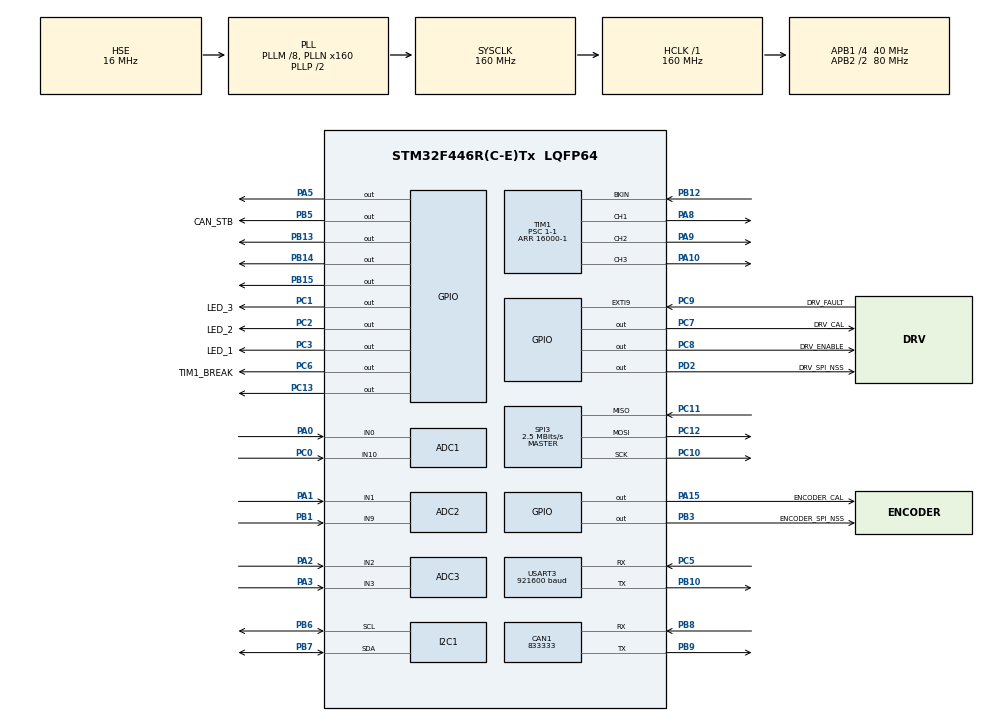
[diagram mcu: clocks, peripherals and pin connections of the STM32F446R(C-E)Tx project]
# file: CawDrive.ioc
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ADC1.Channel-0\#ChannelRegularConversion=ADC_CHANNEL_10
ADC1.Channel-1\#ChannelInjectedConversion=ADC_CHANNEL_0
ADC1.ExternalTrigInjecConv=ADC_EXTERNALTRIGINJECCONV_T1_CC4
ADC1.InjNumberOfConversion=1
ADC1.InjectedOffset-1\#ChannelInjectedConversion=0
ADC1.InjectedRank-1\#ChannelInjectedConversion=1
ADC1.NbrOfConversionFlag=1
ADC1.Rank-0\#ChannelRegularConversion=1
ADC1.SamplingTime-0\#ChannelRegularConversion=ADC_SAMPLETIME_3CYCLES
ADC1.SamplingTime-1\#ChannelInjectedConversion=ADC_SAMPLETIME_3CYCLES
ADC1.master=1
ADC2.Channel-1\#ChannelRegularConversion=ADC_CHANNEL_9
ADC2.Channel-2\#ChannelInjectedConversion=ADC_CHANNEL_1
ADC2.ExternalTrigInjecConv=ADC_EXTERNALTRIGINJECCONV_T1_CC4
ADC2.InjNumberOfConversion=1
ADC2.InjectedOffset-2\#ChannelInjectedConversion=0
ADC2.InjectedRank-2\#ChannelInjectedConversion=1
ADC2.NbrOfConversionFlag=1
ADC2.Rank-1\#ChannelRegularConversion=1
ADC2.SamplingTime-1\#ChannelRegularConversion=ADC_SAMPLETIME_3CYCLES
ADC2.SamplingTime-2\#ChannelInjectedConversion=ADC_SAMPLETIME_3CYCLES
ADC3.Channel-0\#ChannelRegularConversion=ADC_CHANNEL_3
ADC3.Channel-1\#ChannelInjectedConversion=ADC_CHANNEL_2
ADC3.ExternalTrigInjecConv=ADC_EXTERNALTRIGINJECCONV_T1_CC4
ADC3.InjNumberOfConversion=1
ADC3.InjectedOffset-1\#ChannelInjectedConversion=0
ADC3.InjectedRank-1\#ChannelInjectedConversion=1
ADC3.NbrOfConversionFlag=1
ADC3.Rank-0\#ChannelRegularConversion=1
ADC3.SamplingTime-0\#ChannelRegularConversion=ADC_SAMPLETIME_3CYCLES
ADC3.SamplingTime-1\#ChannelInjectedConversion=ADC_SAMPLETIME_3CYCLES
CAN1.BS1=CAN_BS1_1TQ
CAN1.BS2=CAN_BS2_1TQ
CAN1.CalculateBaudRate=833333
CAN1.CalculateTimeBit=1200
CAN1.CalculateTimeQuantum=400.0
Dma.Request0=USART3_TX
Dma.Request1=USART3_RX
Dma.USART3_RX.1.Direction=DMA_PERIPH_TO_MEMORY
Dma.USART3_RX.1.FIFOMode=DMA_FIFOMODE_DISABLE
Dma.USART3_RX.1.Instance=DMA1_Stream1
Dma.USART3_RX.1.MemDataAlignment=DMA_MDATAALIGN_BYTE
Dma.USART3_RX.1.MemInc=DMA_MINC_ENABLE
Dma.USART3_RX.1.Mode=DMA_NORMAL
Dma.USART3_RX.1.PeriphDataAlignment=DMA_PDATAALIGN_BYTE
Dma.USART3_RX.1.PeriphInc=DMA_PINC_DISABLE
Dma.USART3_RX.1.Priority=DMA_PRIORITY_LOW
Dma.USART3_TX.0.Direction=DMA_MEMORY_TO_PERIPH
Dma.USART3_TX.0.FIFOMode=DMA_FIFOMODE_DISABLE
Dma.USART3_TX.0.Instance=DMA1_Stream3
Dma.USART3_TX.0.MemDataAlignment=DMA_MDATAALIGN_BYTE
Dma.USART3_TX.0.MemInc=DMA_MINC_ENABLE
Dma.USART3_TX.0.Mode=DMA_NORMAL
Dma.USART3_TX.0.PeriphDataAlignment=DMA_PDATAALIGN_BYTE
Dma.USART3_TX.0.PeriphInc=DMA_PINC_DISABLE
Dma.USART3_TX.0.Priority=DMA_PRIORITY_LOW
Mcu.Family=STM32F4
Mcu.Name=STM32F446R(C-E)Tx
Mcu.Package=LQFP64
NVIC.ADC_IRQn=true\:0\:0\:false\:false\:true\:true\:true\:true
NVIC.DMA1_Stream1_IRQn=true\:0\:0\:false\:false\:true\:false\:true\:true
NVIC.DMA1_Stream3_IRQn=true\:0\:0\:false\:false\:true\:false\:true\:true
NVIC.PriorityGroup=NVIC_PRIORITYGROUP_4
NVIC.TIM1_BRK_TIM9_IRQn=true\:0\:0\:false\:false\:true\:true\:true\:true
NVIC.TIM1_CC_IRQn=true\:0\:0\:false\:false\:true\:true\:true\:true
NVIC.TIM1_UP_TIM10_IRQn=true\:0\:0\:false\:false\:true\:true\:true\:true
NVIC.TIM3_IRQn=true\:0\:0\:false\:false\:true\:true\:true\:true
NVIC.TIM6_DAC_IRQn=true\:15\:0\:false\:false\:true\:false\:true\:true
NVIC.TimeBase=TIM6_DAC_IRQn
NVIC.TimeBaseIP=TIM6
NVIC.USART3_IRQn=true\:0\:0\:false\:false\:true\:true\:true\:true
PA0-WKUP.Signal=ADCx_IN0
PA1.Signal=ADCx_IN1
PA10.Signal=S_TIM1_CH3
PA13.Mode=Serial_Wire
PA13.Signal=SYS_JTMS-SWDIO
PA14.Mode=Serial_Wire
PA14.Signal=SYS_JTCK-SWCLK
PA15.GPIO_Label=ENCODER_CAL
PA15.Signal=GPIO_Output
PA2.Signal=ADCx_IN2
PA3.Signal=ADCx_IN3
PA5.Signal=GPIO_Output
PA6.Signal=S_TIM3_CH1
PA7.Signal=S_TIM3_CH2
PA8.Signal=S_TIM1_CH1
PA9.Signal=S_TIM1_CH2
PB0.Signal=S_TIM3_CH3
PB1.Signal=ADCx_IN9
PB10.Mode=Asynchronous
PB10.Signal=USART3_TX
PB12.Mode=Activate-Break-Input
PB12.Signal=TIM1_BKIN
PB13.PinState=GPIO_PIN_RESET
PB13.Signal=GPIO_Output
PB14.PinState=GPIO_PIN_RESET
PB14.Signal=GPIO_Output
PB15.PinState=GPIO_PIN_RESET
PB15.Signal=GPIO_Output
PB3.GPIO_Label=ENCODER_SPI_NSS
PB3.PinState=GPIO_PIN_SET
PB3.Signal=GPIO_Output
PB5.GPIO_Label=CAN_STB
PB5.Signal=GPIO_Output
PB6.Mode=I2C
PB6.Signal=I2C1_SCL
PB7.Mode=I2C
PB7.Signal=I2C1_SDA
PB8.Mode=CAN_Activate
PB8.Signal=CAN1_RX
PB9.Mode=CAN_Activate
PB9.Signal=CAN1_TX
PC0.Signal=ADCx_IN10
PC1.GPIO_Label=LED_3
PC1.Signal=GPIO_Output
PC10.Mode=Full_Duplex_Master
PC10.Signal=SPI3_SCK
PC11.Mode=Full_Duplex_Master
PC11.Signal=SPI3_MISO
PC12.Mode=Full_Duplex_Master
PC12.Signal=SPI3_MOSI
PC13.Signal=GPIO_Output
PC2.GPIO_Label=LED_2
PC2.Signal=GPIO_Output
PC3.GPIO_Label=LED_1
PC3.Signal=GPIO_Output
PC5.Mode=Asynchronous
PC5.Signal=USART3_RX
PC6.GPIO_Label=TIM1_BREAK
PC6.Signal=GPIO_Output
PC7.GPIO_Label=DRV_CAL
PC7.Signal=GPIO_Output
PC8.GPIO_Label=DRV_ENABLE
PC8.Signal=GPIO_Output
PC9.GPIO_Label=DRV_FAULT
PC9.Signal=GPXTI9
PD2.GPIO_Label=DRV_SPI_NSS
PD2.PinState=GPIO_PIN_SET
PD2.Signal=GPIO_Output
PH0-OSC_IN.Mode=HSE-External-Oscillator
PH0-OSC_IN.Signal=RCC_OSC_IN
PH1-OSC_OUT.Mode=HSE-External-Oscillator
PH1-OSC_OUT.Signal=RCC_OSC_OUT
ProjectManager.HeapSize=0x200
ProjectManager.StackSize=0x400
ProjectManager.TargetToolchain=Makefile
RCC.AHBFreq_Value=160000000
RCC.APB1CLKDivider=RCC_HCLK_DIV4
RCC.APB1Freq_Value=40000000
RCC.APB1TimFreq_Value=80000000
RCC.APB2CLKDivider=RCC_HCLK_DIV2
RCC.APB2Freq_Value=80000000
RCC.APB2TimFreq_Value=160000000
RCC.CortexFreq_Value=160000000
RCC.HCLKFreq_Value=160000000
RCC.HSE_VALUE=16000000
RCC.PLLM=8
RCC.PLLN=160
RCC.PLLSourceVirtual=RCC_PLLSOURCE_HSE
RCC.SYSCLKFreq_VALUE=160000000
RCC.SYSCLKSource=RCC_SYSCLKSOURCE_PLLCLK
RCC.USBFreq_Value=160000000
RCC.VCOOutputFreq_Value=320000000
SH.ADCx_IN0.0=ADC1_IN0,IN0
SH.ADCx_IN1.0=ADC2_IN1,IN1
SH.ADCx_IN10.0=ADC1_IN10,IN10
SH.ADCx_IN2.0=ADC3_IN2,IN2
SH.ADCx_IN3.0=ADC3_IN3,IN3
SH.ADCx_IN9.0=ADC2_IN9,IN9
SH.S_TIM1_CH1.0=TIM1_CH1,PWM Generation1 CH1
SH.S_TIM1_CH2.0=TIM1_CH2,PWM Generation2 CH2
SH.S_TIM1_CH3.0=TIM1_CH3,PWM Generation3 CH3
SH.S_TIM3_CH1.0=TIM3_CH1
SH.S_TIM3_CH2.0=TIM3_CH2
SH.S_TIM3_CH3.0=TIM3_CH3
SPI3.BaudRatePrescaler=SPI_BAUDRATEPRESCALER_16
SPI3.CLKPhase=SPI_PHASE_2EDGE
SPI3.CalculateBaudRate=2.5 MBits/s
SPI3.DataSize=SPI_DATASIZE_16BIT
SPI3.Direction=SPI_DIRECTION_2LINES
SPI3.Mode=SPI_MODE_MASTER
SPI3.VirtualType=VM_MASTER
STMicroelectronics.X-CUBE-ALGOBUILD.1.4.0.LibraryCcDSPOoLibraryJjDSPOoLibrary=true
TIM1.AutomaticOutput=TIM_AUTOMATICOUTPUT_DISABLE
TIM1.BreakState=TIM_BREAK_ENABLE
TIM1.Channel-PWM\ Generation1\ CH1=TIM_CHANNEL_1
TIM1.Channel-PWM\ Generation2\ CH2=TIM_CHANNEL_2
TIM1.Channel-PWM\ Generation3\ CH3=TIM_CHANNEL_3
TIM1.Channel-PWM\ Generation4\ No\ Output=TIM_CHANNEL_4
TIM1.ClockDivision=TIM_CLOCKDIVISION_DIV2
TIM1.CounterMode=TIM_COUNTERMODE_CENTERALIGNED1
TIM1.OCMode_PWM-PWM\ Generation4\ No\ Output=TIM_OCMODE_PWM2
TIM1.OffStateIDLEMode=TIM_OSSI_DISABLE
TIM1.OffStateRunMode=TIM_OSSR_DISABLE
TIM1.Period=16000-1
TIM1.Prescaler=1-1
TIM1.Pulse-PWM\ Generation4\ No\ Output=16000-2
TIM1.RepetitionCounter=1
TIM3.AutoReloadPreload=TIM_AUTORELOAD_PRELOAD_DISABLE
TIM3.Prescaler=8-1
USART3.BaudRate=921600
USART3.VirtualMode=VM_ASYNC
VP_STMicroelectronics.X-CUBE-ALGOBUILD_VS_DSPOoLibraryJjLibrary_1.4.0_1.4.0.Mode=DSPOoLibraryJjLibrary
VP_SYS_VS_tim6.Mode=TIM6
VP_TIM1_VS_ClockSourceINT.Mode=Internal
VP_TIM1_VS_no_output4.Mode=PWM Generation4 No Output
VP_TIM3_VS_ClockSourceINT.Mode=Internal
board=custom

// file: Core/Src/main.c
/* USER CODE BEGIN Header */
/**
 ******************************************************************************
 * @file           : main.c
 * @brief          : Main program body
 ******************************************************************************
 * @attention
 *
 * Copyright (c) 2025 STMicroelectronics.
 * All rights reserved.
 *
 * This software is licensed under terms that can be found in the LICENSE file
 * in the root directory of this software component.
 * If no LICENSE file comes with this software, it is provided AS-IS.
 *
 ******************************************************************************
 */
/* USER CODE END Header */
#include "main.h"
#include "adc.h"
#include "can.h"
#include "dma.h"
#include "i2c.h"
#include "spi.h"
#include "tim.h"
#include "usart.h"
#include "gpio.h"

/* USER CODE BEGIN Includes */
#include "controller.h"
/* USER CODE END Includes */

void SystemClock_Config(void);

int main(void)
{

  /* MCU Configuration--------------------------------------------------------*/

  /* Reset of all peripherals, Initializes the Flash interface and the Systick. */
  HAL_Init();

  /* Configure the system clock */
  SystemClock_Config();

  /* Initialize all configured peripherals */
  MX_GPIO_Init();
  MX_DMA_Init();
  MX_CAN1_Init();
  MX_TIM1_Init();
  MX_ADC1_Init();
  MX_ADC2_Init();
  MX_ADC3_Init();
  MX_I2C1_Init();
  MX_SPI3_Init();
  MX_USART3_UART_Init();
  MX_TIM3_Init();
  /* USER CODE BEGIN 2 */

  HAL_Delay(10);
  controller_init();

  // drv8323_init(&driver, &hspi3);

  /* USER CODE END 2 */

  /* Infinite loop */
  while (1) {

    /* USER CODE BEGIN 3 */
    HAL_Delay(10);

    controller_step();
  }
  /* USER CODE END 3 */
}

void SystemClock_Config(void)
{
  RCC_OscInitTypeDef RCC_OscInitStruct = {0};
  RCC_ClkInitTypeDef RCC_ClkInitStruct = {0};

  /** Configure the main internal regulator output voltage
  */
  __HAL_RCC_PWR_CLK_ENABLE();
  __HAL_PWR_VOLTAGESCALING_CONFIG(PWR_REGULATOR_VOLTAGE_SCALE1);

  /** Initializes the RCC Oscillators according to the specified parameters
  * in the RCC_OscInitTypeDef structure.
  */
  RCC_OscInitStruct.OscillatorType = RCC_OSCILLATORTYPE_HSE;
  RCC_OscInitStruct.HSEState = RCC_HSE_ON;
  RCC_OscInitStruct.PLL.PLLState = RCC_PLL_ON;
  RCC_OscInitStruct.PLL.PLLSource = RCC_PLLSOURCE_HSE;
  RCC_OscInitStruct.PLL.PLLM = 8;
  RCC_OscInitStruct.PLL.PLLN = 160;
  RCC_OscInitStruct.PLL.PLLP = RCC_PLLP_DIV2;
  RCC_OscInitStruct.PLL.PLLQ = 2;
  RCC_OscInitStruct.PLL.PLLR = 2;
  if (HAL_RCC_OscConfig(&RCC_OscInitStruct) != HAL_OK)
  {
    Error_Handler();
  }

  /** Initializes the CPU, AHB and APB buses clocks
  */
  RCC_ClkInitStruct.ClockType = RCC_CLOCKTYPE_HCLK|RCC_CLOCKTYPE_SYSCLK
                              |RCC_CLOCKTYPE_PCLK1|RCC_CLOCKTYPE_PCLK2;
  RCC_ClkInitStruct.SYSCLKSource = RCC_SYSCLKSOURCE_PLLCLK;
  RCC_ClkInitStruct.AHBCLKDivider = RCC_SYSCLK_DIV1;
  RCC_ClkInitStruct.APB1CLKDivider = RCC_HCLK_DIV4;
  RCC_ClkInitStruct.APB2CLKDivider = RCC_HCLK_DIV2;

  if (HAL_RCC_ClockConfig(&RCC_ClkInitStruct, FLASH_LATENCY_5) != HAL_OK)
  {
    Error_Handler();
  }
}

void HAL_TIM_PeriodElapsedCallback(TIM_HandleTypeDef *htim)
{
  if (htim->Instance == TIM6)
  {
    HAL_IncTick();
  }
}

void Error_Handler(void)
{
  __disable_irq();
  while (1) {
  }
}

#ifdef  USE_FULL_ASSERT
/**
  * @brief  Reports the name of the source file and the source line number
  *         where the assert_param error has occurred.
  * @param  file: pointer to the source file name
  * @param  line: assert_param error line source number
  * @retval None
  */
void assert_failed(uint8_t *file, uint32_t line)
{
  /* USER CODE BEGIN 6 */
  /* User can add his own implementation to report the file name and line
     number, ex: printf("Wrong parameters value: file %s on line %d\r\n", file,
     line) */
  /* USER CODE END 6 */
}
#endif /* USE_FULL_ASSERT */
